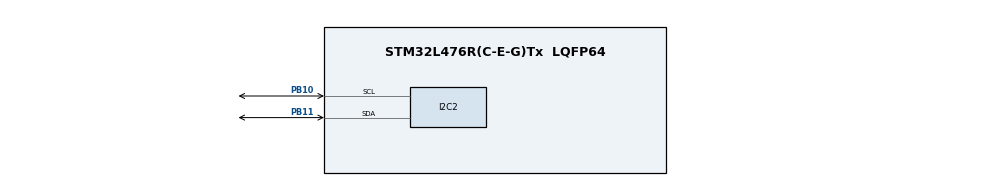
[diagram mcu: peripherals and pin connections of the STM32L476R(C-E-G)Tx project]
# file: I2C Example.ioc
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I2C2.Timing=0x00100D14
Mcu.Family=STM32L4
Mcu.Name=STM32L476R(C-E-G)Tx
Mcu.Package=LQFP64
NVIC.PriorityGroup=NVIC_PRIORITYGROUP_4
PB10.Mode=I2C
PB10.Signal=I2C2_SCL
PB11.Mode=I2C
PB11.Signal=I2C2_SDA
ProjectManager.HeapSize=0x200
ProjectManager.StackSize=0x400
ProjectManager.TargetToolchain=STM32CubeIDE
RCC.HSE_VALUE=8000000
RCC.HSI_VALUE=16000000
RCC.LSE_VALUE=32768
RCC.MSI_VALUE=4000000
RCC.VCOOutputFreq_Value=32000000
board=custom

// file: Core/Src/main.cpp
/* USER CODE BEGIN Header */
/**
  ******************************************************************************
  * @file           : main.c
  * @brief          : Main program body
  ******************************************************************************
  * @attention
  *
  * Copyright (c) 2025 STMicroelectronics.
  * All rights reserved.
  *
  * This software is licensed under terms that can be found in the LICENSE file
  * in the root directory of this software component.
  * If no LICENSE file comes with this software, it is provided AS-IS.
  *
  ******************************************************************************
  */
/* USER CODE END Header */
#include <main.hpp>

/* USER CODE BEGIN PD */
#define SENSOR_ADDR 0x40
/* USER CODE END PD */

I2C_HandleTypeDef hi2c2;

void SystemClock_Config(void);
static void MX_GPIO_Init(void);
static void MX_I2C2_Init(void);
/* USER CODE BEGIN PFP */
uint32_t millis();
/* USER CODE END PFP */

/* USER CODE BEGIN 0 */

void SEND(char port, char data)
{
	/*uint8_t buff[2];
	buff[0] = port;
	buff[1] = data;

	HAL_I2C_Master_Transmit(&hi2c2, I2C_ADDRESS, buff, 2, 1000);*/
}

uint32_t millis() {
    return HAL_GetTick();   // Gibt ms seit HAL_Init() zurück
}

/* USER CODE END 0 */

int main(void)
{

  /* MCU Configuration--------------------------------------------------------*/

  /* Reset of all peripherals, Initializes the Flash interface and the Systick. */
  HAL_Init();

  /* Configure the system clock */
  SystemClock_Config();

  /* Initialize all configured peripherals */
  MX_GPIO_Init();
  MX_I2C2_Init();
  /* USER CODE BEGIN 2 */
  uint16_t data;
  data = 1234;

  INA226 INA((0x40 << 1), &hi2c2);

  if(INA.begin())
  {
	  __NOP();
  }
  else
  {
	  __NOP();
  }

  float shunt = 0.118f;
  float current_LSB_mA = 2.5f;
  float current_zero_offset_mA = 0;
  uint16_t bus_V_scaling_e4 = 9872;

  int configure = INA.configure(shunt, current_LSB_mA, current_zero_offset_mA, bus_V_scaling_e4);
  if(configure)
  {
	  __NOP();
  }
  else
  {
	  __NOP();
  }
  /* USER CODE END 2 */

  /* Infinite loop */
  while (1)
  {

    /* USER CODE BEGIN 3 */
  /*if(HAL_I2C_Mem_Read(&hi2c2, SENSOR_ADDR<<1, 0x0C, I2C_MEMADD_SIZE_8BIT, &data, 2, HAL_MAX_DELAY) == HAL_OK){
	  __NOP();
  } else {
	 __NOP();
  }*/

  float voltage_raw = INA.getBusVoltage_mV() / 1000.0f;
  float current_raw = INA.getCurrent_mA();

  HAL_Delay(100);
  }
  /* USER CODE END 3 */
}

void SystemClock_Config(void)
{
  RCC_OscInitTypeDef RCC_OscInitStruct = {0};
  RCC_ClkInitTypeDef RCC_ClkInitStruct = {0};

  /** Configure the main internal regulator output voltage
  */
  if (HAL_PWREx_ControlVoltageScaling(PWR_REGULATOR_VOLTAGE_SCALE1) != HAL_OK)
  {
    Error_Handler();
  }

  /** Initializes the RCC Oscillators according to the specified parameters
  * in the RCC_OscInitTypeDef structure.
  */
  RCC_OscInitStruct.OscillatorType = RCC_OSCILLATORTYPE_MSI;
  RCC_OscInitStruct.MSIState = RCC_MSI_ON;
  RCC_OscInitStruct.MSICalibrationValue = 0;
  RCC_OscInitStruct.MSIClockRange = RCC_MSIRANGE_6;
  RCC_OscInitStruct.PLL.PLLState = RCC_PLL_NONE;
  if (HAL_RCC_OscConfig(&RCC_OscInitStruct) != HAL_OK)
  {
    Error_Handler();
  }

  /** Initializes the CPU, AHB and APB buses clocks
  */
  RCC_ClkInitStruct.ClockType = RCC_CLOCKTYPE_HCLK|RCC_CLOCKTYPE_SYSCLK
                              |RCC_CLOCKTYPE_PCLK1|RCC_CLOCKTYPE_PCLK2;
  RCC_ClkInitStruct.SYSCLKSource = RCC_SYSCLKSOURCE_MSI;
  RCC_ClkInitStruct.AHBCLKDivider = RCC_SYSCLK_DIV1;
  RCC_ClkInitStruct.APB1CLKDivider = RCC_HCLK_DIV1;
  RCC_ClkInitStruct.APB2CLKDivider = RCC_HCLK_DIV1;

  if (HAL_RCC_ClockConfig(&RCC_ClkInitStruct, FLASH_LATENCY_0) != HAL_OK)
  {
    Error_Handler();
  }
}

static void MX_I2C2_Init(void)
{

  hi2c2.Instance = I2C2;
  hi2c2.Init.Timing = 0x00100D14;
  hi2c2.Init.OwnAddress1 = 0;
  hi2c2.Init.AddressingMode = I2C_ADDRESSINGMODE_7BIT;
  hi2c2.Init.DualAddressMode = I2C_DUALADDRESS_DISABLE;
  hi2c2.Init.OwnAddress2 = 0;
  hi2c2.Init.OwnAddress2Masks = I2C_OA2_NOMASK;
  hi2c2.Init.GeneralCallMode = I2C_GENERALCALL_DISABLE;
  hi2c2.Init.NoStretchMode = I2C_NOSTRETCH_DISABLE;
  if (HAL_I2C_Init(&hi2c2) != HAL_OK)
  {
    Error_Handler();
  }

  /** Configure Analogue filter
  */
  if (HAL_I2CEx_ConfigAnalogFilter(&hi2c2, I2C_ANALOGFILTER_ENABLE) != HAL_OK)
  {
    Error_Handler();
  }

  /** Configure Digital filter
  */
  if (HAL_I2CEx_ConfigDigitalFilter(&hi2c2, 0) != HAL_OK)
  {
    Error_Handler();
  }

}

static void MX_GPIO_Init(void)
{

  /* GPIO Ports Clock Enable */
  __HAL_RCC_GPIOB_CLK_ENABLE();

}

void Error_Handler(void)
{
  __disable_irq();
  while (1)
  {
  }
}
